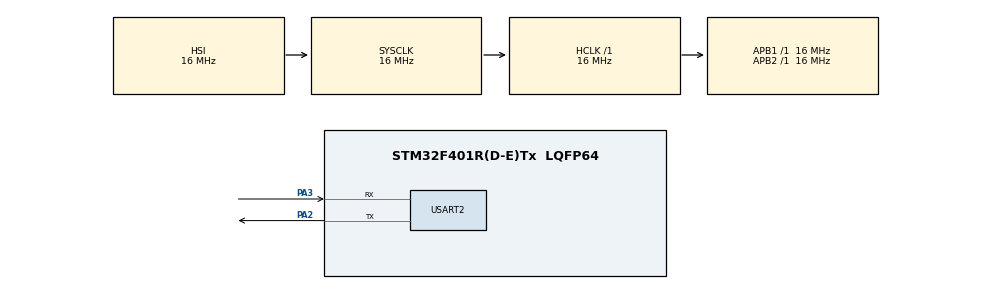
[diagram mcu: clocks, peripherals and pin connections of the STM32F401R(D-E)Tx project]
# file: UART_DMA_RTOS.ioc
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Dma.Request0=USART2_RX
Dma.Request1=USART2_TX
Dma.USART2_RX.0.Direction=DMA_PERIPH_TO_MEMORY
Dma.USART2_RX.0.FIFOMode=DMA_FIFOMODE_DISABLE
Dma.USART2_RX.0.Instance=DMA1_Stream5
Dma.USART2_RX.0.MemDataAlignment=DMA_MDATAALIGN_BYTE
Dma.USART2_RX.0.MemInc=DMA_MINC_ENABLE
Dma.USART2_RX.0.Mode=DMA_NORMAL
Dma.USART2_RX.0.PeriphDataAlignment=DMA_PDATAALIGN_BYTE
Dma.USART2_RX.0.PeriphInc=DMA_PINC_DISABLE
Dma.USART2_RX.0.Priority=DMA_PRIORITY_LOW
Dma.USART2_TX.1.Direction=DMA_MEMORY_TO_PERIPH
Dma.USART2_TX.1.FIFOMode=DMA_FIFOMODE_DISABLE
Dma.USART2_TX.1.Instance=DMA1_Stream6
Dma.USART2_TX.1.MemDataAlignment=DMA_MDATAALIGN_BYTE
Dma.USART2_TX.1.MemInc=DMA_MINC_ENABLE
Dma.USART2_TX.1.Mode=DMA_NORMAL
Dma.USART2_TX.1.PeriphDataAlignment=DMA_PDATAALIGN_BYTE
Dma.USART2_TX.1.PeriphInc=DMA_PINC_DISABLE
Dma.USART2_TX.1.Priority=DMA_PRIORITY_LOW
FREERTOS.BinarySemaphores01=BinSemUART,Dynamic,NULL
FREERTOS.Tasks01=UARTTask1,24,256,StartUARTTask1,Default,NULL,Dynamic,NULL,NULL;UARTTask2,24,256,StartUARTTask2,Default,NULL,Dynamic,NULL,NULL
FREERTOS.configGENERATE_RUN_TIME_STATS=1
FREERTOS.configRECORD_STACK_HIGH_ADDRESS=0
FREERTOS.configUSE_STATS_FORMATTING_FUNCTIONS=1
Mcu.Family=STM32F4
Mcu.Name=STM32F401R(D-E)Tx
Mcu.Package=LQFP64
NVIC.DMA1_Stream5_IRQn=true\:5\:0\:false\:false\:true\:true\:false\:true\:true
NVIC.DMA1_Stream6_IRQn=true\:5\:0\:false\:false\:true\:true\:false\:true\:true
NVIC.PriorityGroup=NVIC_PRIORITYGROUP_4
NVIC.TIM4_IRQn=true\:15\:0\:false\:false\:true\:false\:false\:true\:true
NVIC.TimeBase=TIM4_IRQn
NVIC.TimeBaseIP=TIM4
NVIC.USART2_IRQn=true\:5\:0\:false\:false\:true\:true\:true\:true\:true
PA13.Mode=Trace_Asynchronous_SW
PA13.Signal=SYS_JTMS-SWDIO
PA14.Mode=Trace_Asynchronous_SW
PA14.Signal=SYS_JTCK-SWCLK
PA2.Mode=Asynchronous
PA2.Signal=USART2_TX
PA3.Mode=Asynchronous
PA3.Signal=USART2_RX
PB3.Mode=Trace_Asynchronous_SW
PB3.Signal=SYS_JTDO-SWO
ProjectManager.HeapSize=0x200
ProjectManager.StackSize=0x400
ProjectManager.TargetToolchain=STM32CubeIDE
RCC.AHBFreq_Value=16000000
RCC.APB1Freq_Value=16000000
RCC.APB2Freq_Value=16000000
RCC.CortexFreq_Value=16000000
RCC.HSE_VALUE=25000000
RCC.HSI_VALUE=16000000
RCC.LSE_VALUE=32768
RCC.SYSCLKFreq_VALUE=16000000
RCC.VCOOutputFreq_Value=192000000
USART2.VirtualMode=VM_ASYNC
VP_FREERTOS_VS_CMSIS_V2.Mode=CMSIS_V2
VP_SYS_VS_tim4.Mode=TIM4
board=custom

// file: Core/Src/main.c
/* USER CODE BEGIN Header */
/**
  ******************************************************************************
  * @file           : main.c
  * @brief          : Main program body
  ******************************************************************************
  * @attention
  *
  * Copyright (c) 2023 STMicroelectronics.
  * All rights reserved.
  *
  * This software is licensed under terms that can be found in the LICENSE file
  * in the root directory of this software component.
  * If no LICENSE file comes with this software, it is provided AS-IS.
  *
  ******************************************************************************
  */
/* USER CODE END Header */
#include "main.h"
#include "cmsis_os.h"

/* USER CODE BEGIN Includes */
#include "string.h"
/* USER CODE END Includes */

/* USER CODE BEGIN PD */
#define BUFFER_SIZE 16
#define MAIN_BUFFER_SIZE 48
/* USER CODE END PD */

UART_HandleTypeDef huart2;
DMA_HandleTypeDef hdma_usart2_rx;
DMA_HandleTypeDef hdma_usart2_tx;

/* Definitions for UARTTask1 */
osThreadId_t UARTTask1Handle;
const osThreadAttr_t UARTTask1_attributes = {
  .name = "UARTTask1",
  .stack_size = 256 * 4,
  .priority = (osPriority_t) osPriorityNormal,
};
/* Definitions for UARTTask2 */
osThreadId_t UARTTask2Handle;
const osThreadAttr_t UARTTask2_attributes = {
  .name = "UARTTask2",
  .stack_size = 256 * 4,
  .priority = (osPriority_t) osPriorityNormal,
};
/* Definitions for BinSemUART */
osSemaphoreId_t BinSemUARTHandle;
const osSemaphoreAttr_t BinSemUART_attributes = {
  .name = "BinSemUART"
};
/* USER CODE BEGIN PV */
uint8_t state  = 0;
uint8_t rxBuff[BUFFER_SIZE]={0};
uint8_t mainBuff[MAIN_BUFFER_SIZE]={0};

uint16_t newpos = 0;
uint16_t oldpos = 0;
/* USER CODE END PV */

void SystemClock_Config(void);
static void MX_GPIO_Init(void);
static void MX_DMA_Init(void);
static void MX_USART2_UART_Init(void);
void StartUARTTask1(void *argument);
void StartUARTTask2(void *argument);

/* USER CODE BEGIN PFP */
void Task_action(char *message);
void Send_data(const char *message);
/* USER CODE END PFP */

int main(void)
{

  /* MCU Configuration--------------------------------------------------------*/

  /* Reset of all peripherals, Initializes the Flash interface and the Systick. */
  HAL_Init();

  /* Configure the system clock */
  SystemClock_Config();

  /* Initialize all configured peripherals */
  MX_GPIO_Init();
  MX_DMA_Init();
  MX_USART2_UART_Init();

  /* Init scheduler */
  osKernelInitialize();

  /* Create the semaphores(s) */
  /* creation of BinSemUART */
  BinSemUARTHandle = osSemaphoreNew(1, 0, &BinSemUART_attributes);

  /* Create the thread(s) */
  /* creation of UARTTask1 */
  UARTTask1Handle = osThreadNew(StartUARTTask1, NULL, &UARTTask1_attributes);

  /* creation of UARTTask2 */
  UARTTask2Handle = osThreadNew(StartUARTTask2, NULL, &UARTTask2_attributes);

  /* Start scheduler */
  osKernelStart();
  /* We should never get here as control is now taken by the scheduler */
  /* Infinite loop */
  while (1)
  {

  }
}

void SystemClock_Config(void)
{
  RCC_OscInitTypeDef RCC_OscInitStruct = {0};
  RCC_ClkInitTypeDef RCC_ClkInitStruct = {0};

  /** Configure the main internal regulator output voltage
  */
  __HAL_RCC_PWR_CLK_ENABLE();
  __HAL_PWR_VOLTAGESCALING_CONFIG(PWR_REGULATOR_VOLTAGE_SCALE2);

  /** Initializes the RCC Oscillators according to the specified parameters
  * in the RCC_OscInitTypeDef structure.
  */
  RCC_OscInitStruct.OscillatorType = RCC_OSCILLATORTYPE_HSI;
  RCC_OscInitStruct.HSIState = RCC_HSI_ON;
  RCC_OscInitStruct.HSICalibrationValue = RCC_HSICALIBRATION_DEFAULT;
  RCC_OscInitStruct.PLL.PLLState = RCC_PLL_NONE;
  if (HAL_RCC_OscConfig(&RCC_OscInitStruct) != HAL_OK)
  {
    Error_Handler();
  }

  /** Initializes the CPU, AHB and APB buses clocks
  */
  RCC_ClkInitStruct.ClockType = RCC_CLOCKTYPE_HCLK|RCC_CLOCKTYPE_SYSCLK
                              |RCC_CLOCKTYPE_PCLK1|RCC_CLOCKTYPE_PCLK2;
  RCC_ClkInitStruct.SYSCLKSource = RCC_SYSCLKSOURCE_HSI;
  RCC_ClkInitStruct.AHBCLKDivider = RCC_SYSCLK_DIV1;
  RCC_ClkInitStruct.APB1CLKDivider = RCC_HCLK_DIV1;
  RCC_ClkInitStruct.APB2CLKDivider = RCC_HCLK_DIV1;

  if (HAL_RCC_ClockConfig(&RCC_ClkInitStruct, FLASH_LATENCY_0) != HAL_OK)
  {
    Error_Handler();
  }
}

static void MX_USART2_UART_Init(void)
{

  huart2.Instance = USART2;
  huart2.Init.BaudRate = 115200;
  huart2.Init.WordLength = UART_WORDLENGTH_8B;
  huart2.Init.StopBits = UART_STOPBITS_1;
  huart2.Init.Parity = UART_PARITY_NONE;
  huart2.Init.Mode = UART_MODE_TX_RX;
  huart2.Init.HwFlowCtl = UART_HWCONTROL_NONE;
  huart2.Init.OverSampling = UART_OVERSAMPLING_16;
  if (HAL_UART_Init(&huart2) != HAL_OK)
  {
    Error_Handler();
  }

}

static void MX_DMA_Init(void)
{

  /* DMA controller clock enable */
  __HAL_RCC_DMA1_CLK_ENABLE();

  /* DMA interrupt init */
  /* DMA1_Stream5_IRQn interrupt configuration */
  HAL_NVIC_SetPriority(DMA1_Stream5_IRQn, 5, 0);
  HAL_NVIC_EnableIRQ(DMA1_Stream5_IRQn);
  /* DMA1_Stream6_IRQn interrupt configuration */
  HAL_NVIC_SetPriority(DMA1_Stream6_IRQn, 5, 0);
  HAL_NVIC_EnableIRQ(DMA1_Stream6_IRQn);

}

static void MX_GPIO_Init(void)
{

  /* GPIO Ports Clock Enable */
  __HAL_RCC_GPIOA_CLK_ENABLE();
  __HAL_RCC_GPIOB_CLK_ENABLE();

}

/* USER CODE BEGIN 4 */
void Task_action(char *message)
{
	while(*message){
		ITM_SendChar(*message++);
	}

	ITM_SendChar('\n');
}

void Send_data(const char *message)
{
	HAL_UART_Transmit_DMA(&huart2, (uint8_t *)message, strlen(message));
}

/*event callback when uart finish receive data/idle*/
void HAL_UARTEx_RxEventCallback(UART_HandleTypeDef *huart, uint16_t Size)
{
	if(huart->Instance == USART2){
		/*copy data from rx buffer (little size) to main buffer (big size)*/
		oldpos = newpos;
		memcpy((uint8_t *)mainBuff+oldpos,rxBuff,Size);
		newpos = oldpos+Size;

		/*Receive remain data when the data size is bigger than buffer size*/
		HAL_UARTEx_ReceiveToIdle_DMA(&huart2, (uint8_t*)rxBuff, BUFFER_SIZE);
		__HAL_DMA_DISABLE_IT(&hdma_usart2_rx,DMA_IT_HT);

		state = 2;
	}
//	osSemaphoreRelease(BinSemUARTHandle);

}
/* USER CODE END 4 */

void StartUARTTask1(void *argument)
{
  /* USER CODE BEGIN 5 */
  /* Infinite loop */
  for(;;)
  {
	  Send_data("send 1\n");
	  Task_action("transmit");
	  state = 1;
	  osSemaphoreRelease(BinSemUARTHandle);
    osDelay(2000);
  }
  /* USER CODE END 5 */
}

void StartUARTTask2(void *argument)
{
  /* USER CODE BEGIN StartUARTTask2 */
  /* Infinite loop */

  for(;;)
  {
	  osSemaphoreAcquire(BinSemUARTHandle, 4000);
	  HAL_UARTEx_ReceiveToIdle_DMA(&huart2, (uint8_t*)rxBuff, BUFFER_SIZE);
	  __HAL_DMA_DISABLE_IT(&hdma_usart2_rx,DMA_IT_HT);//disable interrupt half-transfer to trigger event callback
	  Task_action((char *)mainBuff);
  }
  /* USER CODE END StartUARTTask2 */
}

void HAL_TIM_PeriodElapsedCallback(TIM_HandleTypeDef *htim)
{
  if (htim->Instance == TIM4) {
    HAL_IncTick();
  }
}

void Error_Handler(void)
{
  __disable_irq();
  while (1)
  {
  }
}
